# MK22F12810 register map
Vendor: Freescale Semiconductor, Inc.; Series: Kinetis_K; File version: 1.6
CPU: CM4 r0p1, little endian, no MPU, FPU, VTOR, 4 interrupt priority bits
Registers are 32-bit, read-write, reset 0x0 unless marked. A register's access mark holds for its fields unless they carry their own. Offsets are from the block's base; [hi:lo] are bit positions; {n}, {i} and the like mark numbered series.

## PIT — Periodic Interrupt Timer
Base 0x40037000; register names take the prefix PIT_
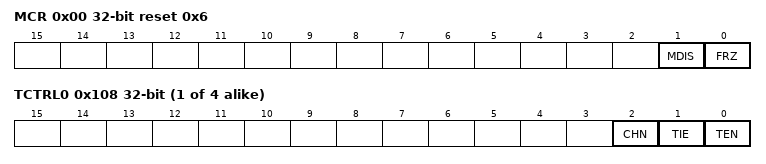
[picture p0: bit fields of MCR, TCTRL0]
0x00 MCR reset 0x6 — PIT Module Control Register
  [1] MDIS — Module Disable - (PIT section)
    0=Clock for standard PIT timers is enabled; 1=Clock for standard PIT timers is disabled
  [0] FRZ — Freeze
    0=Timers continue to run in Debug mode; 1=Timers are stopped in Debug mode
{0x100+0x10*i} LDVAL{i} (i=0..3) — Timer Load Value Register
  [31:0] TSV — Timer Start Value
{0x104+0x10*i} CVAL{i} (i=0..3) ro — Current Timer Value Register
  [31:0] TVL — Current Timer Value
{0x108+0x10*i} TCTRL{i} (i=0..3) — Timer Control Register
  [2] CHN — Chain Mode
    0=Timer is not chained; 1=Timer is chained to previous timer. For example, for Channel 2, if this field is set, Timer 2 is chained to Timer 1.
  [1] TIE — Timer Interrupt Enable
    0=Interrupt requests from Timer n are disabled; 1=Interrupt will be requested whenever TIF is set
  [0] TEN — Timer Enable
    0=Timer n is disabled; 1=Timer n is enabled
{0x10C+0x10*i} TFLG{i} (i=0..3) — Timer Flag Register
  [0] TIF — Timer Interrupt Flag
    0=Timeout has not yet occurred; 1=Timeout has occurred

## RFVBAT — VBAT register file
Base 0x4003E000; register names take the prefix RFVBAT_
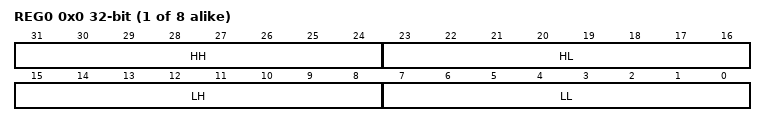
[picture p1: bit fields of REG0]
{0x0+4i} REG{i} (i=0..7) — VBAT register file register
  [31:24] HH — High higher byte
  [23:16] HL — High lower byte
  [15:8] LH — Low higher byte
  [7:0] LL — Low lower byte

## DAC0 — 12-Bit Digital-to-Analog Converter
Base 0x4003F000; register names take the prefix DAC0_
{0x0+2i} DAT{i}L (i=0..15) 8-bit — DAC Data Low Register
  [7:0] DATA0 — When the DAC buffer is not enabled, DATA[11:0] controls the output voltage based on the following formula: V out = V in * (1 + DACDAT0[11:0])/4096 When the DAC buffer is enabled, DATA is mapped to the 16-word buffer
{0x1+2i} DAT{i}H (i=0..15) 8-bit — DAC Data High Register
  [3:0] DATA1 — When the DAC Buffer is not enabled, DATA[11:0] controls the output voltage based on the following formula
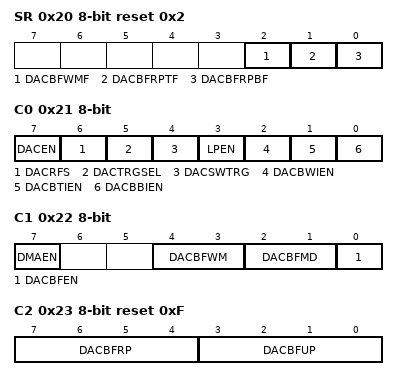
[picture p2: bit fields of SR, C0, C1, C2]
0x20 SR 8-bit reset 0x2 — DAC Status Register
  [2] DACBFWMF — DAC Buffer Watermark Flag
    0=The DAC buffer read pointer has not reached the watermark level; 1=The DAC buffer read pointer has reached the watermark level
  [1] DACBFRPTF — DAC Buffer Read Pointer Top Position Flag
    0=The DAC buffer read pointer is not zero; 1=The DAC buffer read pointer is zero
  [0] DACBFRPBF — DAC Buffer Read Pointer Bottom Position Flag
    0=The DAC buffer read pointer is not equal to C2[DACBFUP]; 1=The DAC buffer read pointer is equal to C2[DACBFUP]
0x21 C0 8-bit — DAC Control Register
  [7] DACEN — DAC Enable
    0=The DAC system is disabled; 1=The DAC system is enabled
  [6] DACRFS — DAC Reference Select
    0=The DAC selects DACREF_1 as the reference voltage; 1=The DAC selects DACREF_2 as the reference voltage
  [5] DACTRGSEL — DAC Trigger Select
    0=The DAC hardware trigger is selected; 1=The DAC software trigger is selected
  [4] DACSWTRG wo — DAC Software Trigger
    0=The DAC soft trigger is not valid; 1=The DAC soft trigger is valid
  [3] LPEN — DAC Low Power Control
    0=High-Power mode; 1=Low-Power mode
  [2] DACBWIEN — DAC Buffer Watermark Interrupt Enable
    0=The DAC buffer watermark interrupt is disabled; 1=The DAC buffer watermark interrupt is enabled
  [1] DACBTIEN — DAC Buffer Read Pointer Top Flag Interrupt Enable
    0=The DAC buffer read pointer top flag interrupt is disabled; 1=The DAC buffer read pointer top flag interrupt is enabled
  [0] DACBBIEN — DAC Buffer Read Pointer Bottom Flag Interrupt Enable
    0=The DAC buffer read pointer bottom flag interrupt is disabled; 1=The DAC buffer read pointer bottom flag interrupt is enabled
0x22 C1 8-bit — DAC Control Register 1
  [7] DMAEN — DMA Enable Select
    0=DMA is disabled; 1=DMA is enabled. When DMA is enabled, the DMA request will be generated by original interrupts. The interrupts will not be presented on this module at the same time.
  [4:3] DACBFWM — DAC Buffer Watermark Select
    0=In normal mode, 1 word . In FIFO mode, 2 or less than 2 data remaining in FIFO will set watermark status bit.; 1=In normal mode, 2 words . In FIFO mode, Max/4 or less than Max/4 data remaining in FIFO will set watermark status bit.; 2=In normal mode, 3 words . In FIFO mode, Max/2 or less than Max/2 data remaining in FIFO will set watermark status bit.; 3=In normal mode, 4 words . In FIFO mode, Max-2 or less than Max-2 data remaining in FIFO will set watermark status bit.
  [2:1] DACBFMD — DAC Buffer Work Mode Select
    0=Normal mode; 1=Swing mode; 2=One-Time Scan mode; 3=FIFO mode
  [0] DACBFEN — DAC Buffer Enable
    0=Buffer read pointer is disabled. The converted data is always the first word of the buffer.; 1=Buffer read pointer is enabled. The converted data is the word that the read pointer points to. It means converted data can be from any word of the buffer.
0x23 C2 8-bit reset 0xF — DAC Control Register 2
  [7:4] DACBFRP — DAC Buffer Read Pointer
  [3:0] DACBFUP — DAC Buffer Upper Limit

## Notices in the file
Redistribution and use in source and binary forms, with or without modification,
are permitted provided that the following conditions are met:
o Redistributions of source code must retain the above copyright notice, this list
of conditions and the following disclaimer.
o Redistributions in binary form must reproduce the above copyright notice, this
list of conditions and the following disclaimer in the documentation and/or
other materials provided with the distribution.
o Neither the name of Freescale Semiconductor, Inc. nor the names of its
contributors may be used to endorse or promote products derived from this
software without specific prior written permission.
THIS SOFTWARE IS PROVIDED BY THE COPYRIGHT HOLDERS AND CONTRIBUTORS "AS IS" AND
ANY EXPRESS OR IMPLIED WARRANTIES, INCLUDING, BUT NOT LIMITED TO, THE IMPLIED
WARRANTIES OF MERCHANTABILITY AND FITNESS FOR A PARTICULAR PURPOSE ARE
DISCLAIMED. IN NO EVENT SHALL THE COPYRIGHT HOLDER OR CONTRIBUTORS BE LIABLE FOR
ANY DIRECT, INDIRECT, INCIDENTAL, SPECIAL, EXEMPLARY, OR CONSEQUENTIAL DAMAGES
(INCLUDING, BUT NOT LIMITED TO, PROCUREMENT OF SUBSTITUTE GOODS OR SERVICES;
LOSS OF USE, DATA, OR PROFITS; OR BUSINESS INTERRUPTION) HOWEVER CAUSED AND ON
ANY THEORY OF LIABILITY, WHETHER IN CONTRACT, STRICT LIABILITY, OR TORT
(INCLUDING NEGLIGENCE OR OTHERWISE) ARISING IN ANY WAY OUT OF THE USE OF THIS
SOFTWARE, EVEN IF ADVISED OF THE POSSIBILITY OF SUCH DAMAGE.
